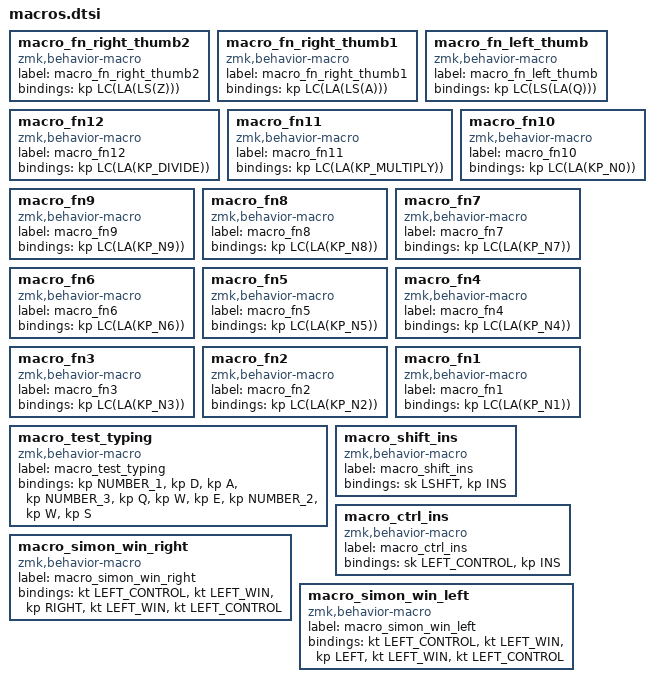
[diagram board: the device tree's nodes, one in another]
macro_fn_right_thumb2: macro_fn_right_thumb2{
compatible = "zmk,behavior-macro";
label = "macro_fn_right_thumb2";
#binding-cells = <0>;
bindings = <&kp LC(LA(LS(Z)))>;
};
macro_fn_right_thumb1: macro_fn_right_thumb1{
compatible = "zmk,behavior-macro";
label = "macro_fn_right_thumb1";
#binding-cells = <0>;
bindings = <&kp LC(LA(LS(A)))>;
};
macro_fn_left_thumb: macro_fn_left_thumb{
compatible = "zmk,behavior-macro";
label = "macro_fn_left_thumb";
#binding-cells = <0>;
bindings = <&kp LC(LS(LA(Q)))>;
};
macro_fn12: macro_fn12{
compatible = "zmk,behavior-macro";
label = "macro_fn12";
#binding-cells = <0>;
bindings = <&kp LC(LA(KP_DIVIDE))>;
};
macro_fn11: macro_fn11{
compatible = "zmk,behavior-macro";
label = "macro_fn11";
#binding-cells = <0>;
bindings = <&kp LC(LA(KP_MULTIPLY))>;
};
macro_fn10: macro_fn10{
compatible = "zmk,behavior-macro";
label = "macro_fn10";
#binding-cells = <0>;
bindings = <&kp LC(LA(KP_N0))>;
};
macro_fn9: macro_fn9{
compatible = "zmk,behavior-macro";
label = "macro_fn9";
#binding-cells = <0>;
bindings = <&kp LC(LA(KP_N9))>;
};
macro_fn8: macro_fn8{
compatible = "zmk,behavior-macro";
label = "macro_fn8";
#binding-cells = <0>;
bindings = <&kp LC(LA(KP_N8))>;
};
macro_fn7: macro_fn7{
compatible = "zmk,behavior-macro";
label = "macro_fn7";
#binding-cells = <0>;
bindings = <&kp LC(LA(KP_N7))>;
};
macro_fn6: macro_fn6{
compatible = "zmk,behavior-macro";
label = "macro_fn6";
#binding-cells = <0>;
bindings = <&kp LC(LA(KP_N6))>;
};
macro_fn5: macro_fn5{
compatible = "zmk,behavior-macro";
label = "macro_fn5";
#binding-cells = <0>;
bindings = <&kp LC(LA(KP_N5))>;
};
macro_fn4: macro_fn4{
compatible = "zmk,behavior-macro";
label = "macro_fn4";
#binding-cells = <0>;
bindings = <&kp LC(LA(KP_N4))>;
};
macro_fn3: macro_fn3{
compatible = "zmk,behavior-macro";
label = "macro_fn3";
#binding-cells = <0>;
bindings = <&kp LC(LA(KP_N3))>;
};
macro_fn2: macro_fn2{
compatible = "zmk,behavior-macro";
label = "macro_fn2";
#binding-cells = <0>;
bindings = <&kp LC(LA(KP_N2))>;
};
macro_fn1: macro_fn1{
compatible = "zmk,behavior-macro";
label = "macro_fn1";
#binding-cells = <0>;
bindings = <&kp LC(LA(KP_N1))>;
};
macro_test_typing: macro_test_typing{
compatible = "zmk,behavior-macro";
label = "macro_test_typing";
#binding-cells = <0>;
bindings = <&kp NUMBER_1>, <&kp D>, <&kp A>, <&kp NUMBER_3>, <&kp Q>, <&kp W>, <&kp E>, <&kp NUMBER_2>, <&kp W>, <&kp S>;
};
macro_shift_ins: macro_shift_ins{
compatible = "zmk,behavior-macro";
label = "macro_shift_ins";
#binding-cells = <0>;
bindings = <&sk LSHFT>, <&kp INS>;
};
macro_ctrl_ins: macro_ctrl_ins{
compatible = "zmk,behavior-macro";
label = "macro_ctrl_ins";
#binding-cells = <0>;
bindings = <&sk LEFT_CONTROL>, <&kp INS>;
};
macro_simon_win_right: macro_simon_win_right{
compatible = "zmk,behavior-macro";
label = "macro_simon_win_right";
#binding-cells = <0>;
bindings = <&kt LEFT_CONTROL>, <&kt LEFT_WIN>, <&kp RIGHT>, <&kt LEFT_WIN>, <&kt LEFT_CONTROL>;
};
macro_simon_win_left: macro_simon_win_left{
compatible = "zmk,behavior-macro";
label = "macro_simon_win_left";
#binding-cells = <0>;
bindings = <&kt LEFT_CONTROL>, <&kt LEFT_WIN>, <&kp LEFT>, <&kt LEFT_WIN>, <&kt LEFT_CONTROL>;
};
